AUTOSAR XML (schema 4-2-2)
package /Components
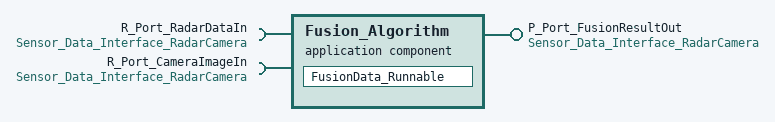
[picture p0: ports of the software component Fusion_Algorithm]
  application sw component type Fusion_Algorithm
    provide port P_Port_FusionResultOut: provided-interface=Sensor_Data_Interface_RadarCamera
    require port R_Port_RadarDataIn: required-interface=Sensor_Data_Interface_RadarCamera
    require port R_Port_CameraImageIn: required-interface=Sensor_Data_Interface_RadarCamera
    behavior FusionAlgorithm_BHV
      data received event FusionInputReady: start-on-event=FusionData_Runnable
      runnable FusionData_Runnable: symbol=FusionSymbol
        data-receive-point-by-arguments:
          access RadarInput: accessed-variable={autosar-variable-in-impl-datatype={port-prototype=R_Port_RadarDataIn, target-data-prototype=RadarData}, autosar-variable=R_Port_RadarDataIn.RadarData}
          access CameraInput: accessed-variable={autosar-variable-in-impl-datatype={port-prototype=R_Port_CameraImageIn, target-data-prototype=CameraImageData}, autosar-variable=R_Port_CameraImageIn.CameraImageData}
        data-send-points:
          access FusionResultOutput: accessed-variable={autosar-variable-in-impl-datatype={port-prototype=P_Port_FusionResultOut, target-data-prototype=Timestamp}, autosar-variable=P_Port_FusionResultOut.Timestamp}
